# STM32C5A3 register map
File version: 0.1
CPU: CM33 r0p4, little endian, MPU, FPU, 4 interrupt priority bits
Registers are 32-bit, read-write, reset 0x0 unless marked. A register's access mark holds for its fields unless they carry their own. Offsets are from the block's base; [hi:lo] are bit positions; {n}, {i} and the like mark numbered series; 'fields as' and 'values as' point back to an identical list.

## IWDG — IWDG address block description
Base 0x40003000
0x00 IWDG_KR wo — IWDG key register
  [15:0] KEY — Key value (write only, read 0x0000)
0x04 IWDG_PR — IWDG prescaler register
  [3:0] PR — Prescaler divider
    0=divider / 4; 1=divider / 8; 2=divider / 16; 3=divider / 32; 4=divider / 64; 5=divider / 128; 6=divider / 256; 7=divider / 512
0x08 IWDG_RLR reset 0xFFF — IWDG reload register
  [11:0] RL — Watchdog counter reload value
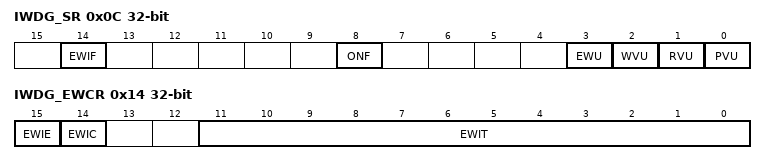
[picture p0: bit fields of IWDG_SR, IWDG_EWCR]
0x0C IWDG_SR ro — IWDG status register
  [14] EWIF — Watchdog early interrupt flag
  [8] ONF — Watchdog enable status bit
    0=The IWDG is not activated; 1=The IWDG is activated and needs to be refreshed regularly by the application
  [3] EWU — Watchdog interrupt comparator value update
  [2] WVU — Watchdog counter window value update
  [1] RVU — Watchdog counter reload value update
  [0] PVU — Watchdog prescaler value update
0x10 IWDG_WINR reset 0xFFF — IWDG window register
  [11:0] WIN — Watchdog counter window value
0x14 IWDG_EWCR — IWDG early wake-up interrupt register
  [15] EWIE — Watchdog early interrupt enable
    0=The early interrupt interface is disabled; 1=The early interrupt interface is enabled
  [14] EWIC wo — Watchdog early interrupt acknowledge
  [11:0] EWIT — Watchdog counter window value

## RAMCFG — RAMCFG register block
Base 0x40026000
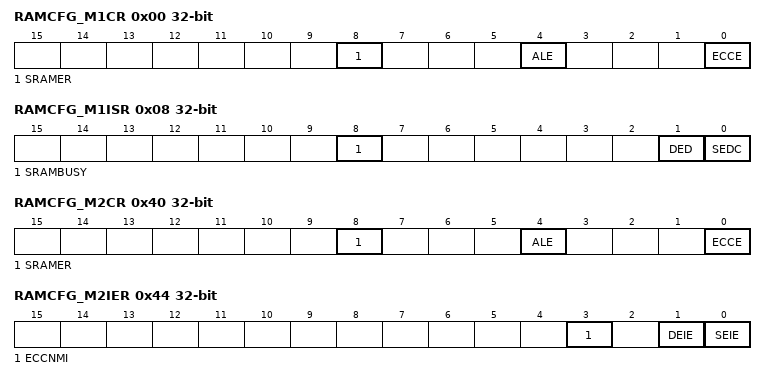
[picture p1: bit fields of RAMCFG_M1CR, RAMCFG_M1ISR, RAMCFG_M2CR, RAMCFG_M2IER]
0x00 RAMCFG_M1CR (reset mask 0xFFFFFFF0) — RAMCFG memory 1 control register
  [8] SRAMER — SRAM erase
    0=No erase operation ongoing; 1=Erase operation ongoing
  [4] ALE — Address latch enable
    0=Failing address not stored in the SRAMx ECC single/double error address registers; 1=Failing address stored in the SRAMx ECC single/double error address registers
  [0] ECCE — ECC enable.
    0=ECC disabled; 1=ECC enabled
0x08 RAMCFG_M1ISR ro — RAMCFG memory 1 interrupt status register
  [8] SRAMBUSY — SRAM busy with erase operation
    0=No erase operation ongoing; 1=Erase operation ongoing
  [1] DED — ECC double error detected
    0=No double error; 1=Double error detected
  [0] SEDC — ECC single error detected and corrected
    0=No single error; 1=Single error detected and corrected
0x28 RAMCFG_M1ERKEYR wo — RAMCFG memory 1 erase key register
  [7:0] ERASEKEY — Erase write protection key
0x40 RAMCFG_M2CR (reset mask 0xFFFFFFF0) — RAMCFG memory 2 control register
  fields as RAMCFG_M1CR
0x44 RAMCFG_M2IER — RAMCFG memory 2 interrupt enable register
  [3] ECCNMI — Double error NMI
    0=NMI not generated in case of ECC double error; 1=NMI generated in case of ECC double error
  [1] DEIE — ECC double error interrupt enable
    0=Double error interrupt disabled; 1=Double error interrupt enabled
  [0] SEIE — ECC single error interrupt enable
    0=Single error interrupt disabled; 1=Single error interrupt enabled
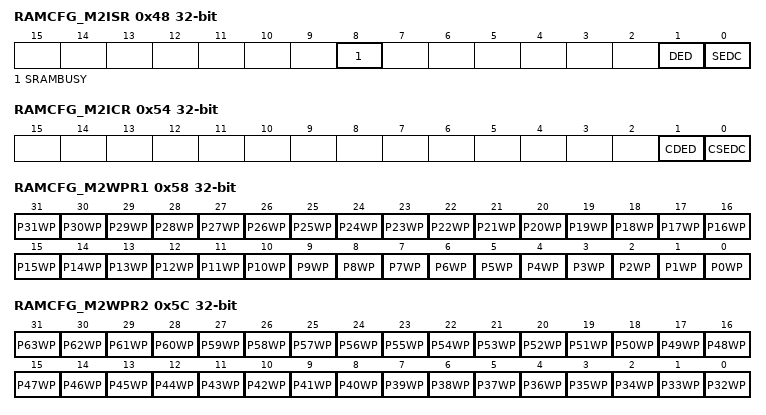
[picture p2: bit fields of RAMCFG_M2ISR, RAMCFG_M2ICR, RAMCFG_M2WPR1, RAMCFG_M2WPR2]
0x48 RAMCFG_M2ISR ro — RAMCFG memory 2 interrupt status register
  fields as RAMCFG_M1ISR
0x4C RAMCFG_M2SEAR ro — RAMCFG memory 2 ECC single error address register
  [31:0] ESEA — ECC single error address
0x50 RAMCFG_M2DEAR ro — RAMCFG memory 2 ECC double error address register
  [31:0] EDEA — ECC double error address
0x54 RAMCFG_M2ICR — RAMCFG memory 2 interrupt clear register
  [1] CDED — Clear ECC double error detected
  [0] CSEDC — Clear ECC single error detected and corrected
0x58 RAMCFG_M2WPR1 — RAMCFG memory 2 write protection register 1
  [all] fields
    0=Write protection of SRAM2 1-Kbyte page y is disabled; 1=Write protection of SRAM2 1-Kbyte page y is enabled
  [n] P{n}WP (n=0..31) — SRAM2 1-Kbyte page y write protection
0x5C RAMCFG_M2WPR2 — RAMCFG memory 2 write protection register 2
  [all] fields
    values as the fields of RAMCFG_M2WPR1
  [n-32] P{n}WP (n=32..63) — SRAM2 1-Kbyte page y write protection
0x64 RAMCFG_M2ECCKEYR wo — RAMCFG memory 2ECC key register
  [7:0] ECCKEY — ECC write protection key
0x68 RAMCFG_M2ERKEYR wo — RAMCFG memory 2 erase key register
  [7:0] ERASEKEY — Erase write protection key
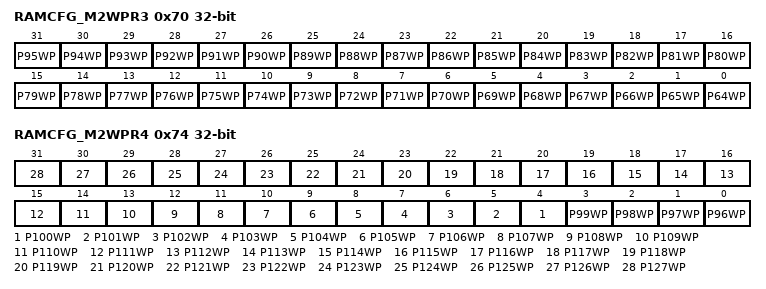
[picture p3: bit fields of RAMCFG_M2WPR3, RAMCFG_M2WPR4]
0x70 RAMCFG_M2WPR3 — RAMCFG memory 2 write protection register 3
  [all] fields
    values as the fields of RAMCFG_M2WPR1
  [n-64] P{n}WP (n=64..95) — SRAM2 1-Kbyte page y write protection
0x74 RAMCFG_M2WPR4 — RAMCFG memory 2 write protection register 4
  [all] fields
    values as the fields of RAMCFG_M2WPR1
  [n-96] P{n}WP (n=96..127) — SRAM2 1-Kbyte page y write protection
